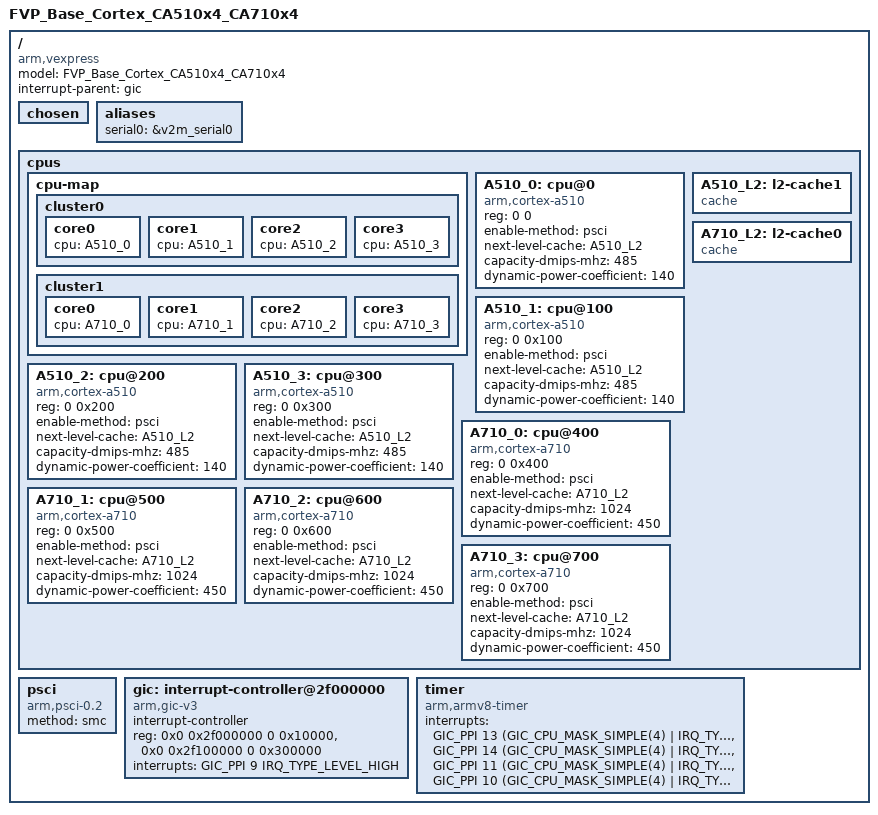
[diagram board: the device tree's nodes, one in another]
/*
 * SPDX-License-Identifier: Apache-2.0
 * Copyright (c) 2019 KapaXL (kapa.xl@outlook.com)
 *
 * FVP_Base_Cortex_CA510x4_CA710x4
 * FVP_Base_Cortex_CA55x4_CA75x4
 * FVP_Base_Cortex_CA55x4_CA784
 */

/dts-v1/;

#include "memory.dtsi"
#include "vexpress_ca510x4_ca710x4m.dtsi"

/ {
	model = "FVP_Base_Cortex_CA510x4_CA710x4";
	compatible = "arm,vexpress";
	interrupt-parent = <&gic>;
	#address-cells = <2>;
	#size-cells = <2>;

	chosen { };

	aliases {
		serial0 = &v2m_serial0;
	};

	cpus {
		#address-cells = <2>;
		#size-cells = <0>;

		cpu-map {
			cluster0 {
				core0 {
					cpu = <&A510_0>;
				};
				core1 {
					cpu = <&A510_1>;
				};
				core2 {
					cpu = <&A510_2>;
				};
				core3 {
					cpu = <&A510_3>;
				};
			};

			cluster1 {
				core0 {
					cpu = <&A710_0>;
				};
				core1 {
					cpu = <&A710_1>;
				};
				core2 {
					cpu = <&A710_2>;
				};
				core3 {
					cpu = <&A710_3>;
				};
			};
		};

		A510_0: cpu@0 {
			device_type = "cpu";
			compatible = "arm,cortex-a510";
			reg = <0 0>;
			enable-method = "psci";
			next-level-cache = <&A510_L2>;
			capacity-dmips-mhz = <485>;
			dynamic-power-coefficient = <140>;
		};

		A510_1: cpu@100 {
			device_type = "cpu";
			compatible = "arm,cortex-a510";
			reg = <0 0x100>;
			enable-method = "psci";
			next-level-cache = <&A510_L2>;
			capacity-dmips-mhz = <485>;
			dynamic-power-coefficient = <140>;
		};

		A510_2: cpu@200 {
			device_type = "cpu";
			compatible = "arm,cortex-a510";
			reg = <0 0x200>;
			enable-method = "psci";
			next-level-cache = <&A510_L2>;
			capacity-dmips-mhz = <485>;
			dynamic-power-coefficient = <140>;
		};

		A510_3: cpu@300 {
			device_type = "cpu";
			compatible = "arm,cortex-a510";
			reg = <0 0x300>;
			enable-method = "psci";
			next-level-cache = <&A510_L2>;
			capacity-dmips-mhz = <485>;
			dynamic-power-coefficient = <140>;
		};

		A710_0: cpu@400 {
			device_type = "cpu";
			compatible = "arm,cortex-a710";
			reg = <0 0x400>;
			enable-method = "psci";
			next-level-cache = <&A710_L2>;
			capacity-dmips-mhz = <1024>;
			dynamic-power-coefficient = <450>;
		};

		A710_1: cpu@500 {
			device_type = "cpu";
			compatible = "arm,cortex-a710";
			reg = <0 0x500>;
			enable-method = "psci";
			next-level-cache = <&A710_L2>;
			capacity-dmips-mhz = <1024>;
			dynamic-power-coefficient = <450>;
		};

		A710_2: cpu@600 {
			device_type = "cpu";
			compatible = "arm,cortex-a710";
			reg = <0 0x600>;
			enable-method = "psci";
			next-level-cache = <&A710_L2>;
			capacity-dmips-mhz = <1024>;
			dynamic-power-coefficient = <450>;
		};

		A710_3: cpu@700 {
			device_type = "cpu";
			compatible = "arm,cortex-a710";
			reg = <0 0x700>;
			enable-method = "psci";
			next-level-cache = <&A710_L2>;
			capacity-dmips-mhz = <1024>;
			dynamic-power-coefficient = <450>;
		};

		A510_L2: l2-cache1 {
			compatible = "cache";
		};

		A710_L2: l2-cache0 {
			compatible = "cache";
		};
	};

	psci {
		compatible = "arm,psci-0.2";
		method = "smc";
	};

	gic: interrupt-controller@2f000000 {
		compatible = "arm,gic-v3";
		#interrupt-cells = <3>;

		interrupt-controller;
		reg = <0x0 0x2f000000 0 0x10000>,		// GICD
			  <0x0 0x2f100000 0 0x300000>;		// GICR
		interrupts = <GIC_PPI 9 IRQ_TYPE_LEVEL_HIGH>;
	};

	timer {
		compatible = "arm,armv8-timer";
		interrupts = <GIC_PPI 13 (GIC_CPU_MASK_SIMPLE(4) | IRQ_TYPE_LEVEL_LOW)>,
				 <GIC_PPI 14 (GIC_CPU_MASK_SIMPLE(4) | IRQ_TYPE_LEVEL_LOW)>,
				 <GIC_PPI 11 (GIC_CPU_MASK_SIMPLE(4) | IRQ_TYPE_LEVEL_LOW)>,
				 <GIC_PPI 10 (GIC_CPU_MASK_SIMPLE(4) | IRQ_TYPE_LEVEL_LOW)>;
	};
};
